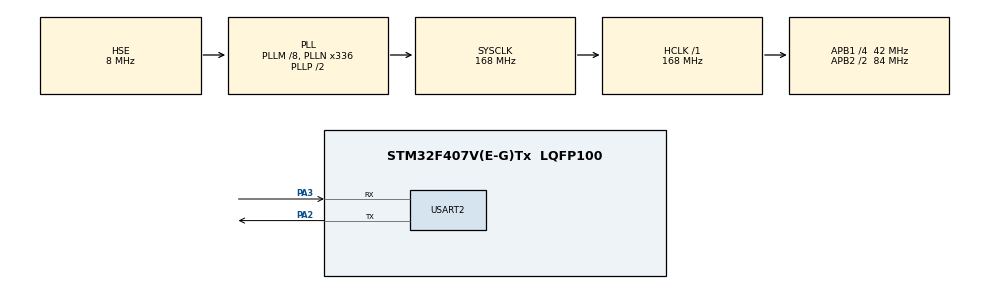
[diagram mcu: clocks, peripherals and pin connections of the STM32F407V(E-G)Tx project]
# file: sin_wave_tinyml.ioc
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Mcu.Family=STM32F4
Mcu.Name=STM32F407V(E-G)Tx
Mcu.Package=LQFP100
NVIC.PriorityGroup=NVIC_PRIORITYGROUP_0
PA2.Mode=Asynchronous
PA2.Signal=USART2_TX
PA3.Mode=Asynchronous
PA3.Signal=USART2_RX
PH0-OSC_IN.Mode=HSE-External-Oscillator
PH0-OSC_IN.Signal=RCC_OSC_IN
PH1-OSC_OUT.Mode=HSE-External-Oscillator
PH1-OSC_OUT.Signal=RCC_OSC_OUT
ProjectManager.HeapSize=0x200
ProjectManager.StackSize=0x400
ProjectManager.TargetToolchain=STM32CubeIDE
RCC.48MHZClocksFreq_Value=48000000
RCC.AHBFreq_Value=168000000
RCC.APB1CLKDivider=RCC_HCLK_DIV4
RCC.APB1Freq_Value=42000000
RCC.APB1TimFreq_Value=84000000
RCC.APB2CLKDivider=RCC_HCLK_DIV2
RCC.APB2Freq_Value=84000000
RCC.APB2TimFreq_Value=168000000
RCC.CortexFreq_Value=168000000
RCC.HCLKFreq_Value=168000000
RCC.HSE_VALUE=8000000
RCC.HSI_VALUE=16000000
RCC.LSE_VALUE=32768
RCC.PLLM=8
RCC.PLLN=336
RCC.PLLQ=7
RCC.PLLSourceVirtual=RCC_PLLSOURCE_HSE
RCC.SYSCLKFreq_VALUE=168000000
RCC.SYSCLKSource=RCC_SYSCLKSOURCE_PLLCLK
RCC.VCOOutputFreq_Value=336000000
STMicroelectronics.X-CUBE-AI.10.2.0.ActivationBufferSizeList=1940
STMicroelectronics.X-CUBE-AI.10.2.0.ActivationBuffers=pool0
STMicroelectronics.X-CUBE-AI.10.2.0.ActivationNames=pool0
STMicroelectronics.X-CUBE-AI.10.2.0.ActivationSizes=AI_NETWORK_DATA_ACTIVATION_1_SIZE
STMicroelectronics.X-CUBE-AI.10.2.0.HeapSize=0x800
STMicroelectronics.X-CUBE-AI.10.2.0.InternalRamActivationBufferMaxSize=AI_NETWORK_DATA_ACTIVATIONS_SIZE
STMicroelectronics.X-CUBE-AI.10.2.0.LatestDirectoryUsed-dc5d6133c3c35928eb640026df0a2c04474dbb3626e4a48bc2d22730e153a63e=D\:\\AI
STMicroelectronics.X-CUBE-AI.10.2.0.MaximumNumberOfInputLayer=1
STMicroelectronics.X-CUBE-AI.10.2.0.MaximumNumberOfOutputLayer=1
STMicroelectronics.X-CUBE-AI.10.2.0.MaximumSizeOfInputLayer=1
STMicroelectronics.X-CUBE-AI.10.2.0.MaximumSizeOfOutputLayer=1
STMicroelectronics.X-CUBE-AI.10.2.0.ModelActualCompression-dc5d6133c3c35928eb640026df0a2c04474dbb3626e4a48bc2d22730e153a63e=0.0
STMicroelectronics.X-CUBE-AI.10.2.0.ModelCompression-dc5d6133c3c35928eb640026df0a2c04474dbb3626e4a48bc2d22730e153a63e=None
STMicroelectronics.X-CUBE-AI.10.2.0.ModelFlashOccupation-dc5d6133c3c35928eb640026df0a2c04474dbb3626e4a48bc2d22730e153a63e=10040
STMicroelectronics.X-CUBE-AI.10.2.0.ModelHashList=dc5d6133c3c35928eb640026df0a2c04474dbb3626e4a48bc2d22730e153a63e
STMicroelectronics.X-CUBE-AI.10.2.0.ModelKind-dc5d6133c3c35928eb640026df0a2c04474dbb3626e4a48bc2d22730e153a63e=TFLITE
STMicroelectronics.X-CUBE-AI.10.2.0.ModelMacc-dc5d6133c3c35928eb640026df0a2c04474dbb3626e4a48bc2d22730e153a63e=353
STMicroelectronics.X-CUBE-AI.10.2.0.ModelName-dc5d6133c3c35928eb640026df0a2c04474dbb3626e4a48bc2d22730e153a63e=network
STMicroelectronics.X-CUBE-AI.10.2.0.ModelNameList=network
STMicroelectronics.X-CUBE-AI.10.2.0.ModelRamOccupation-dc5d6133c3c35928eb640026df0a2c04474dbb3626e4a48bc2d22730e153a63e=1940
STMicroelectronics.X-CUBE-AI.10.2.0.ModelStructureFile-dc5d6133c3c35928eb640026df0a2c04474dbb3626e4a48bc2d22730e153a63e=D\:\\AI\\sine_model.tflite
STMicroelectronics.X-CUBE-AI.10.2.0.ModelType-dc5d6133c3c35928eb640026df0a2c04474dbb3626e4a48bc2d22730e153a63e=STM32Cube.AI MCU runtime
STMicroelectronics.X-CUBE-AI.10.2.0.ReadyForCodeGeneration=true
STMicroelectronics.X-CUBE-AI.10.2.0.StackSize=0x800
STMicroelectronics.X-CUBE-AI.10.2.0.WorkingBufferStartAddrList=0xFFFFFFFF
STMicroelectronics.X-CUBE-AI.10.2.0.XAaCUBEAaAICcArtificialOoIntelligenceJjCore=true
STMicroelectronics.X-CUBE-AI.10.2.0.copyWeightToRam=false
STMicroelectronics.X-CUBE-AI.10.2.0.customLayerConfigEnabled=false
STMicroelectronics.X-CUBE-AI.10.2.0.noOnnxIoTranspose=false
STMicroelectronics.X-CUBE-AI.10.2.0.useInputAllocation=true
STMicroelectronics.X-CUBE-AI.10.2.0.useOutputAllocation=true
USART2.VirtualMode=VM_ASYNC
VP_STMicroelectronics.X-CUBE-AI_VS_ArtificialOoIntelligenceJjXAaCUBEAaAI_10.2.0.Mode=ArtificialOoIntelligenceJjXAaCUBEAaAI
board=STM32F407G-DISC1

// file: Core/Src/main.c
/* USER CODE BEGIN Header */
/**
  ******************************************************************************
  * @file           : main.c
  * @brief          : TinyML Sine inference — STM32F407 Discovery
  ******************************************************************************
  */
/* USER CODE END Header */
#include "main.h"

/* USER CODE BEGIN Includes */
#include "network.h"
#include "network_data.h"
#include "ai_platform.h"
#include <string.h>
/* USER CODE END Includes */

UART_HandleTypeDef huart2;

/* USER CODE BEGIN PV */
AI_ALIGNED(4)
static ai_u8 activations[AI_NETWORK_DATA_ACTIVATIONS_SIZE];

static ai_handle network = AI_HANDLE_NULL;

static ai_buffer *net_input;
static ai_buffer *net_output;

static float in_data[AI_NETWORK_IN_1_SIZE];
static float out_data[AI_NETWORK_OUT_1_SIZE];
/* USER CODE END PV */

void SystemClock_Config(void);
static void MX_GPIO_Init(void);
static void MX_USART2_UART_Init(void);

/* USER CODE BEGIN 0 */
static void UART_Print(const char *msg)
{
    HAL_UART_Transmit(&huart2, (uint8_t *)msg, strlen(msg), HAL_MAX_DELAY);
}

static void UART_PrintFloat(const char *label, float val)
{
    /* Print label first */
    UART_Print(label);

    /* Handle negative */
    if (val < 0.0f)
    {
        HAL_UART_Transmit(&huart2, (uint8_t *)"-", 1, HAL_MAX_DELAY);
        val = -val;
    }

    /* Split into integer and fractional parts */
    int int_part  = (int)val;
    float frac    = val - (float)int_part;
    int frac_part = (int)(frac * 1000000.0f + 0.5f);

    /* Convert integer part to string */
    char tmp[16];
    int i = 0;
    if (int_part == 0)
    {
        tmp[i++] = '0';
    }
    else
    {
        int n = int_part;
        while (n > 0) { tmp[i++] = '0' + (n % 10); n /= 10; }
        /* Reverse */
        for (int a = 0, b = i - 1; a < b; a++, b--)
        {
            char t = tmp[a]; tmp[a] = tmp[b]; tmp[b] = t;
        }
    }
    HAL_UART_Transmit(&huart2, (uint8_t *)tmp, i, HAL_MAX_DELAY);

    /* Decimal point */
    HAL_UART_Transmit(&huart2, (uint8_t *)".", 1, HAL_MAX_DELAY);

    /* Fractional part — always 6 digits with leading zeros */
    char frac_str[7];
    frac_str[6] = '\0';
    for (int j = 5; j >= 0; j--) { frac_str[j] = '0' + (frac_part % 10); frac_part /= 10; }
    HAL_UART_Transmit(&huart2, (uint8_t *)frac_str, 6, HAL_MAX_DELAY);

    HAL_UART_Transmit(&huart2, (uint8_t *)"\r\n", 2, HAL_MAX_DELAY);
}
/* USER CODE END 0 */

int main(void)
{

  /* MCU Configuration--------------------------------------------------------*/

  /* Reset of all peripherals, Initializes the Flash interface and the Systick. */
  HAL_Init();

  /* USER CODE BEGIN Init */
  UART_Print("AJJJJJJ\r\n");

  /* USER CODE END Init */

  /* Configure the system clock */
  SystemClock_Config();

  /* Initialize all configured peripherals */
  MX_GPIO_Init();
  MX_USART2_UART_Init();
  /* USER CODE BEGIN 2 */
  const ai_handle acts[] = { activations };

  ai_error err = ai_network_create_and_init(&network, acts, NULL);
  if (err.type != AI_ERROR_NONE)
  {
      UART_Print("AI Init FAILED\r\n");
      Error_Handler();
  }

  net_input  = ai_network_inputs_get(network, NULL);
  net_output = ai_network_outputs_get(network, NULL);

  UART_Print("AI Init OK\r\n");
  /* USER CODE END 2 */

  /* Infinite loop */
  while (1)
  {

    /* USER CODE BEGIN 3 */
    in_data[0] = 1.5708f;   /* pi/2 — expected sin ~ 1.0 */

    net_input[0].data  = AI_HANDLE_PTR(in_data);
    net_output[0].data = AI_HANDLE_PTR(out_data);

    ai_i32 batch = ai_network_run(network, net_input, net_output);
    if (batch == 1)
    {
        UART_PrintFloat("sin(pi/2) = ", out_data[0]);
    }
    else
    {
        UART_Print("Inference Error\r\n");
    }

    HAL_Delay(1000);
  }
  /* USER CODE END 3 */
}

void SystemClock_Config(void)
{
  RCC_OscInitTypeDef RCC_OscInitStruct = {0};
  RCC_ClkInitTypeDef RCC_ClkInitStruct = {0};

  /** Configure the main internal regulator output voltage
  */
  __HAL_RCC_PWR_CLK_ENABLE();
  __HAL_PWR_VOLTAGESCALING_CONFIG(PWR_REGULATOR_VOLTAGE_SCALE1);

  /** Initializes the RCC Oscillators according to the specified parameters
  * in the RCC_OscInitTypeDef structure.
  */
  RCC_OscInitStruct.OscillatorType = RCC_OSCILLATORTYPE_HSE;
  RCC_OscInitStruct.HSEState = RCC_HSE_ON;
  RCC_OscInitStruct.PLL.PLLState = RCC_PLL_ON;
  RCC_OscInitStruct.PLL.PLLSource = RCC_PLLSOURCE_HSE;
  RCC_OscInitStruct.PLL.PLLM = 8;
  RCC_OscInitStruct.PLL.PLLN = 336;
  RCC_OscInitStruct.PLL.PLLP = RCC_PLLP_DIV2;
  RCC_OscInitStruct.PLL.PLLQ = 7;
  if (HAL_RCC_OscConfig(&RCC_OscInitStruct) != HAL_OK)
  {
    Error_Handler();
  }

  /** Initializes the CPU, AHB and APB buses clocks
  */
  RCC_ClkInitStruct.ClockType = RCC_CLOCKTYPE_HCLK|RCC_CLOCKTYPE_SYSCLK
                              |RCC_CLOCKTYPE_PCLK1|RCC_CLOCKTYPE_PCLK2;
  RCC_ClkInitStruct.SYSCLKSource = RCC_SYSCLKSOURCE_PLLCLK;
  RCC_ClkInitStruct.AHBCLKDivider = RCC_SYSCLK_DIV1;
  RCC_ClkInitStruct.APB1CLKDivider = RCC_HCLK_DIV4;
  RCC_ClkInitStruct.APB2CLKDivider = RCC_HCLK_DIV2;

  if (HAL_RCC_ClockConfig(&RCC_ClkInitStruct, FLASH_LATENCY_5) != HAL_OK)
  {
    Error_Handler();
  }
}

static void MX_USART2_UART_Init(void)
{

  huart2.Instance = USART2;
  huart2.Init.BaudRate = 115200;
  huart2.Init.WordLength = UART_WORDLENGTH_8B;
  huart2.Init.StopBits = UART_STOPBITS_1;
  huart2.Init.Parity = UART_PARITY_NONE;
  huart2.Init.Mode = UART_MODE_TX_RX;
  huart2.Init.HwFlowCtl = UART_HWCONTROL_NONE;
  huart2.Init.OverSampling = UART_OVERSAMPLING_16;
  if (HAL_UART_Init(&huart2) != HAL_OK)
  {
    Error_Handler();
  }

}

static void MX_GPIO_Init(void)
{

  /* GPIO Ports Clock Enable */
  __HAL_RCC_GPIOH_CLK_ENABLE();
  __HAL_RCC_GPIOA_CLK_ENABLE();

}

void Error_Handler(void)
{
  __disable_irq();
  while (1)
  {
  }
}
